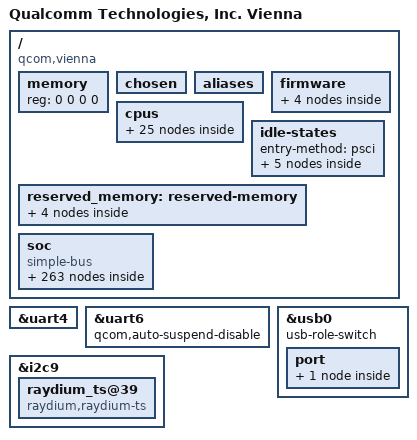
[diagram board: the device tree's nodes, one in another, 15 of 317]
// SPDX-License-Identifier: BSD-3-Clause
/*
 * Copyright (c) Qualcomm Technologies, Inc. and/or its subsidiaries.
 */

#include <dt-bindings/clock/qcom,gcc-vienna.h>
#include <dt-bindings/clock/qcom,gpucc-vienna.h>
#include <dt-bindings/clock/qcom,rpmh.h>
#include <dt-bindings/dma/qcom-gpi.h>
#include <dt-bindings/interrupt-controller/arm-gic.h>
#include <dt-bindings/interconnect/qcom,icc.h>
#include <dt-bindings/interconnect/qcom,vienna.h>
#include <dt-bindings/soc/qcom,rpmh-rsc.h>
#include <dt-bindings/soc/qcom,ipcc.h>
#include <dt-bindings/mailbox/qcom-ipcc-vienna.h>
#include <dt-bindings/regulator/qcom,rpmh-regulator-levels.h>
#include <dt-bindings/spmi/spmi.h>

/ {
	model = "Qualcomm Technologies, Inc. Vienna";
	compatible = "qcom,vienna";
	qcom,msm-id = <669 0x10000 >;
	interrupt-parent = <&intc>;
	#address-cells = <2>;
	#size-cells = <2>;
	memory { device_type = "memory"; reg = <0 0 0 0>; };

	chosen: chosen {
		bootargs = "android_arch_task_struct_size=512 kasan=off kpti=0 log_buf_len=256K swiotlb=0 loop.max_part=7 irqaffinity=0-1 cpufreq.default_governor=performance printk.console_no_auto_verbose=1 rcupdate.rcu_expedited=1 rcu_nocbs=0-4 kernel.panic_on_rcu_stall=1 androidboot.usbcontroller=a600000.dwc3";
	};

	aliases {
		serial0 = &uart4;
		hsuart1 = &uart6;
		i2c0 = &i2c0;
		i2c1 = &i2c1;
		i2c2 = &i2c2_a;
		i2c3 = &i2c3_a;
		i2c4 = &i2c4;
		i2c5 = &i2c5_a;
		i2c6 = &i2c6;
		i2c7 = &i2c7_a;
		i2c8 = &i2c8;
		i2c9 = &i2c9;
		i2c10 = &i2c10;
		i2c11 = &i2c2_b;
		i2c12 = &i2c3_b;
		i2c13 = &i2c5_b;
		i2c14 = &i2c7_b;
		spi0 = &spi0;
		spi1 = &spi1;
		spi2 = &spi2_a;
		spi3 = &spi3_a;
		spi4 = &spi4;
		spi5 = &spi5_a;
		spi6 = &spi6;
		spi7 = &spi7_a;
		spi8 = &spi8;
		spi9 = &spi9;
		spi10 = &spi10;
		spi11 = &spi2_b;
		spi12 = &spi3_b;
		spi13 = &spi5_b;
		spi14 = &spi7_b;
		mmc0 = &sdhc_1;
		mmc1 = &sdhc_3; /*SDC3 SDIO slot*/
	};

	firmware: firmware {

		qcom_scm: qcom_scm {
			compatible = "qcom,scm";
			qcom,dload-mode = <&tcsr 0x19000>;
		};

		qtee_shmbridge {
			compatible = "qcom,tee-shared-memory-bridge";
		};

		qcom_smcinvoke {
			compatible = "qcom,smcinvoke";
		};

		qcom_mem_object {
			compatible = "qcom,mem-object";
		};
	};

	cpus {
		#address-cells = <2>;
		#size-cells = <0>;
		CPU0: cpu@0 {
			device_type = "cpu";
			compatible = "qcom,kryo";
			reg = <0x0 0x0>;
			enable-method = "psci";
			d-cache-size = <0x8000>;
			i-cache-size = <0x8000>;
			cpu-idle-states = <&SILVER_RAIL_OFF>;
			power-domains = <&CPU_PD0>;
			power-domain-names = "psci";
			next-level-cache = <&L2_0>;
			qcom,freq-domain = <&cpufreq_hw 0>;
			capacity-dmips-mhz = <1024>;
			dynamic-power-coefficient = <100>;
			#cooling-cells = <2>;
			L2_0: l2-cache {
			      cache-level = <2>;
			      compatible = "cache";
			      cache-size = <0x10000>;
			};

			L1_I_0: l1-icache {
			      compatible = "cache";
			};

			L1_D_0: l1-dcache {
			      compatible = "cache";
			};
		};

		CPU1: cpu@100 {
			device_type = "cpu";
			compatible = "qcom,kryo";
			reg = <0x0 0x100>;
			enable-method = "psci";
			d-cache-size = <0x8000>;
			i-cache-size = <0x8000>;
			cpu-idle-states = <&SILVER_RAIL_OFF>;
			power-domains = <&CPU_PD1>;
			power-domain-names = "psci";
			next-level-cache = <&L2_0>;
			qcom,freq-domain = <&cpufreq_hw 0>;
			capacity-dmips-mhz = <1024>;
			dynamic-power-coefficient = <100>;
			#cooling-cells = <2>;

			L1_I_1: l1-icache {
			      compatible = "cache";
			};

			L1_D_1: l1-dcache {
			      compatible = "cache";
			};
		};

		CPU2: cpu@200 {
			device_type = "cpu";
			compatible = "qcom,kryo";
			reg = <0x0 0x200>;
			enable-method = "psci";
			d-cache-size = <0x8000>;
			i-cache-size = <0x8000>;
			cpu-idle-states = <&SILVER_RAIL_OFF>;
			power-domains = <&CPU_PD2>;
			power-domain-names = "psci";
			next-level-cache = <&L2_0>;
			qcom,freq-domain = <&cpufreq_hw 0>;
			capacity-dmips-mhz = <1024>;
			dynamic-power-coefficient = <100>;
			#cooling-cells = <2>;

			L1_I_2: l1-icache {
			      compatible = "cache";
			};

			L1_D_2: l1-dcache {
			      compatible = "cache";
			};
		};

		CPU3: cpu@300 {
			device_type = "cpu";
			compatible = "qcom,kryo";
			reg = <0x0 0x300>;
			enable-method = "psci";
			d-cache-size = <0x8000>;
			i-cache-size = <0x8000>;
			cpu-idle-states = <&SILVER_RAIL_OFF>;
			power-domains = <&CPU_PD3>;
			power-domain-names = "psci";
			next-level-cache = <&L2_0>;
			qcom,freq-domain = <&cpufreq_hw 0>;
			capacity-dmips-mhz = <1024>;
			dynamic-power-coefficient = <100>;
			#cooling-cells = <2>;

			L1_I_3: l1-icache {
			      compatible = "cache";
			};

			L1_D_3: l1-dcache {
			      compatible = "cache";
			};
		};

		CPU4: cpu@400 {
			device_type = "cpu";
			compatible = "qcom,kryo";
			reg = <0x0 0x400>;
			enable-method = "psci";
			d-cache-size = <0x8000>;
			i-cache-size = <0x8000>;
			cpu-idle-states = <&GOLD_OFF &GOLD_RAIL_OFF>;
			power-domains = <&CPU_PD4>;
			power-domain-names = "psci";
			next-level-cache = <&L2_1>;
			qcom,freq-domain = <&cpufreq_hw 1>;
			capacity-dmips-mhz = <1946>;
			dynamic-power-coefficient = <472>;
			#cooling-cells = <2>;
			L2_1: l2-cache {
			      cache-level = <2>;
			      compatible = "cache";
			      cache-size = <0x40000>;
			};

			L1_I_4: l1-icache {
			      compatible = "cache";
			};

			L1_D_4: l1-dcache {
			      compatible = "cache";
			};
		};

		cpu-map {
			cluster0 {
				core0 {
					cpu = <&CPU0>;
				};

				core1 {
					cpu = <&CPU1>;
				};

				core2 {
					cpu = <&CPU2>;
				};

				core3 {
					cpu = <&CPU3>;
				};
			};

			cluster1 {
				core0 {
					cpu = <&CPU4>;
				};
			};
		};
	};

	idle-states {
		entry-method = "psci";

		GOLD_OFF: gold-c3 {  /* C3 */
			compatible = "arm,idle-state";
			idle-state-name = "pc";
			entry-latency-us = <400>;
			exit-latency-us = <1050>;
			min-residency-us = <5773>;
			arm,psci-suspend-param = <0x40000003>;
			local-timer-stop;
		};

		GOLD_RAIL_OFF: gold-cluster0-c4 { /* C4 */
			compatible = "arm,idle-state";
			idle-state-name = "rail-pc";
			entry-latency-us = <550>;
			exit-latency-us = <1100>;
			min-residency-us = <9016>;
			arm,psci-suspend-param = <0x40000004>;
			local-timer-stop;
		};

		SILVER_RAIL_OFF: silver-cluster1-c4 { /* C4 */
			compatible = "arm,idle-state";
			idle-state-name = "rail-pc";
			entry-latency-us = <550>;
			exit-latency-us = <900>;
			min-residency-us = <6700>;
			arm,psci-suspend-param = <0x40000004>;
			local-timer-stop;
		};

		CLUSTER_PWR_DN: cluster-d4 { /* D4 */
			compatible = "domain-idle-state";
			idle-state-name = "l3-off";
			entry-latency-us = <750>;
			exit-latency-us = <2350>;
			min-residency-us = <9144>;
			arm,psci-suspend-param = <0x41000044>;
		};

		CX_RET: cx-ret { /* Cx Ret */
			compatible = "domain-idle-state";
			idle-state-name = "cx-ret";
			entry-latency-us = <2800>;
			exit-latency-us = <4400>;
			min-residency-us = <10901>;
			arm,psci-suspend-param = <0x41003344>;
		};
	};

	reserved_memory: reserved-memory { };

	soc: soc { };
};

&qcom_scm {
	compatible = "qcom,scm";
};

&soc {
	#address-cells = <1>;
	#size-cells = <1>;
	ranges = <0 0 0 0xffffffff>;
	compatible = "simple-bus";

	psci {
		compatible = "arm,psci-1.0";
		method = "smc";

		CPU_PD0: cpu-pd0 {
			#power-domain-cells = <0>;
			power-domains = <&CLUSTER_PD>;
		};

		CPU_PD1: cpu-pd1 {
			#power-domain-cells = <0>;
			power-domains = <&CLUSTER_PD>;
		};

		CPU_PD2: cpu-pd2 {
			#power-domain-cells = <0>;
			power-domains = <&CLUSTER_PD>;
		};

		CPU_PD3: cpu-pd3 {
			#power-domain-cells = <0>;
			power-domains = <&CLUSTER_PD>;
		};

		CPU_PD4: cpu-pd4 {
			#power-domain-cells = <0>;
			power-domains = <&CLUSTER_PD>;
		};

		CLUSTER_PD: cluster-pd {
			#power-domain-cells = <0>;
			domain-idle-states = <&CLUSTER_PWR_DN &CX_RET>;
		};
	};

	msm_gpu: qcom,kgsl-3d0@3d00000 { };

	intc: interrupt-controller@17200000 {
		compatible = "arm,gic-v3";
		#interrupt-cells = <3>;
		interrupt-controller;
		#redistributor-regions = <1>;
		redistributor-stride = <0x0 0x20000>;
		reg = <0x17200000 0x10000>,	// GICD
		      <0x17260000 0xA0000>;	// GICR * 5
		interrupts = <GIC_PPI 9 IRQ_TYPE_LEVEL_HIGH>;
	};

	qcom_tzlog: tz-log@14680720 {
		compatible = "qcom,tz-log";
		reg = <0x14680720 0x3000>;
		qcom,hyplog-enabled;
		hyplog-address-offset = <0x410>;
		hyplog-size-offset = <0x414>;
		tmecrashdump-address-offset = <0x81CA0000>;
	};

	memtimer: timer@17420000 {
		#address-cells = <1>;
		#size-cells = <1>;
		ranges;
		compatible = "arm,armv7-timer-mem";
		reg = <0x17420000 0x1000>;
		clock-frequency = <19200000>;
		frame@17421000 {
			frame-number = <0>;
			interrupts = <GIC_SPI 8 IRQ_TYPE_LEVEL_HIGH>,
				     <GIC_SPI 6 IRQ_TYPE_LEVEL_HIGH>;
			reg = <0x17421000 0x1000>,
			      <0x17422000 0x1000>;
		};

		frame@17423000 {
			frame-number = <1>;
			interrupts = <GIC_SPI 9 IRQ_TYPE_LEVEL_HIGH>;
			reg = <0x17423000 0x1000>;
			status = "disabled";
		};

		frame@17425000 {
			frame-number = <2>;
			interrupts = <GIC_SPI 10 IRQ_TYPE_LEVEL_HIGH>;
			reg = <0x17425000 0x1000>;
			status = "disabled";
		};

		frame@17427000 {
			frame-number = <3>;
			interrupts = <GIC_SPI 11 IRQ_TYPE_LEVEL_HIGH>;
			reg = <0x17427000 0x1000>;
			status = "disabled";
		};

		frame@17429000 {
			frame-number = <4>;
			interrupts = <GIC_SPI 12 IRQ_TYPE_LEVEL_HIGH>;
			reg = <0x17429000 0x1000>;
			status = "disabled";
		};

		frame@1742b000 {
			frame-number = <5>;
			interrupts = <GIC_SPI 13 IRQ_TYPE_LEVEL_HIGH>;
			reg = <0x1742b000 0x1000>;
			status = "disabled";
		};

		frame@1742d000 {
			frame-number = <6>;
			interrupts = <GIC_SPI 14 IRQ_TYPE_LEVEL_HIGH>;
			reg = <0x1742d000 0x1000>;
			status = "disabled";
		};
	};

	wdog: qcom,wdt@17410000 {
		compatible = "qcom,msm-watchdog";
		reg = <0x17410000 0x1000>;
		reg-names = "wdt-base";
		interrupts = <GIC_SPI 0 IRQ_TYPE_LEVEL_HIGH>,
			     <GIC_SPI 1 IRQ_TYPE_LEVEL_HIGH>;
		qcom,bark-time = <11000>;
		qcom,pet-time = <9360>;
		qcom,ipi-ping;
		qcom,wakeup-enable;
		status = "ok";
	};

	google,debug-kinfo {
		compatible = "google,debug-kinfo";
		memory-region = <&kinfo_mem>;
	};

	mini_dump_mode {
		compatible = "qcom,minidump";
		status = "ok";
	};

	apps_rsc: rsc@17a00000 {
		label = "apps_rsc";
		compatible = "qcom,rpmh-rsc";
		reg = <0x17a00000 0x10000>,
		      <0x17a10000 0x10000>,
		      <0x17a20000 0x10000>;
		reg-names = "drv-0", "drv-1", "drv-2";
		qcom,drv-count = <3>;
		interrupts = <GIC_SPI 3 IRQ_TYPE_LEVEL_HIGH>,
			     <GIC_SPI 4 IRQ_TYPE_LEVEL_HIGH>,
			     <GIC_SPI 5 IRQ_TYPE_LEVEL_HIGH>;
		power-domains = <&CLUSTER_PD>;

		apps_rsc_drv2: drv@2 {
			qcom,drv-id = <2>;
			qcom,tcs-offset = <0xd00>;
			qcom,tcs-distance = <0x2a0>;
			channel@0 {
				qcom,tcs-config = <ACTIVE_TCS    3>,
						  <SLEEP_TCS     2>,
						  <WAKE_TCS      2>,
						  <CONTROL_TCS   0>,
						  <FAST_PATH_TCS 1>;
			};

			apps_bcm_voter: bcm_voter {
				compatible = "qcom,bcm-voter";
			};

			rpmhcc: clock-controller {
				compatible = "qcom,vienna-rpmh-clk";
				#clock-cells = <1>;
			};
		};
	};

	cluster-device {
		compatible = "qcom,lpm-cluster-dev";
		power-domains = <&CLUSTER_PD>;
	};

	qcom,secure-buffer {
		compatible = "qcom,secure-buffer";
		qcom,vmid-cp-camera-preview-ro;
	};

	pdc: interrupt-controller@b220000 {
		compatible = "qcom,vienna-pdc", "qcom,pdc";
		reg = <0xb220000 0x10000>, <0x174000f0 0x64>;
		qcom,pdc-ranges = <0 456 30>, <38 663 9>, <51 527 47>,
				  <98 608 32>, <130 716 12>, <142 251 5>,
				  <147 584 16>;
		#interrupt-cells = <2>;
		interrupt-parent = <&intc>;
		interrupt-controller;
	};

	show_resume_irqs@17200000 {
		compatible = "qcom,show-resume-irqs";
		reg = <0x17200000 0x130000>;	/* GICD */
	};

	arch_timer: timer {
		compatible = "arm,armv8-timer";
		interrupts = <GIC_PPI 13 (GIC_CPU_MASK_SIMPLE(8) | IRQ_TYPE_LEVEL_LOW)>,
			     <GIC_PPI 14 (GIC_CPU_MASK_SIMPLE(8) | IRQ_TYPE_LEVEL_LOW)>,
			     <GIC_PPI 11 (GIC_CPU_MASK_SIMPLE(8) | IRQ_TYPE_LEVEL_LOW)>,
			     <GIC_PPI 12 (GIC_CPU_MASK_SIMPLE(8) | IRQ_TYPE_LEVEL_LOW)>;
		clock-frequency = <19200000>;
	};

	sdhc1_opp_table: sdhc1-opp-table {
		compatible = "operating-points-v2";

		opp-100000000 {
			opp-hz = /bits/ 64 <100000000>;
			opp-peak-kBps = <250000 133320>;
			opp-avg-kBps = <104000 0>;
		};

		opp-384000000 {
			opp-hz = /bits/ 64 <384000000>;
			opp-peak-kBps = <800000 300000>;
			opp-avg-kBps = <400000 0>;
		};
	};

	sdhc3_opp_table: sdhc3-opp-table {
		compatible = "operating-points-v2";

		opp-100000000 {
			opp-hz = /bits/ 64 <100000000>;
			opp-peak-kBps = <160000 100000>;
			opp-avg-kBps = <50000 0>;
		};

		opp-202000000 {
			opp-hz = /bits/ 64 <202000000>;
			opp-peak-kBps = <200000 120000>;
			opp-avg-kBps = <104000 0>;
		};
	};

	sdhc_1: sdhci@8804000 {
		compatible = "qcom,sdhci-msm-v5";
		status = "disabled";

		reg = <0x08804000 0x1000>,<0x08805000 0x1000>,<0x08808000 0x18000>;
		reg-names = "hc", "cqhci", "ice";

		iommus = <&apps_smmu 0x0120 0x0>;
		qcom,iommu-dma = "fastmap";

		/*
		 * iommu-addresses - Indicate the range of data addresses which will be
		 * used in dma allocation.
		 *
		 * iommu-geometry -  This is specific for fastmap which Allow clients
		 * to save SMMU page table memory.
		 *
		 * The 2nd parameter indicates size of the smmu page table memory.
		 * If its exceeds beyond this size, last unused entry from page table
		 * memory will be invalidated.
		 *
		 * It's better to provide range of dma address, hence provide
		 * iommu-dma-addr-pool property along with iommu-geometry property.
		 */

		qcom,iommu-addresses = <0x40000000 0x10000000>;
		qcom,iommu-geometry = <0x40000000 0x10000000>;

		interrupts = <GIC_SPI 207 IRQ_TYPE_LEVEL_HIGH>,
			<GIC_SPI 223 IRQ_TYPE_LEVEL_HIGH>;
		interrupt-names = "hc_irq", "pwr_irq";

		clocks = <&gcc GCC_SDCC1_APPS_CLK>,
			<&gcc GCC_SDCC1_AHB_CLK>,
			<&gcc GCC_SDCC1_ICE_CORE_CLK>;
		clock-names = "core", "iface", "ice_core";

		qcom,ice-clk-rates = <300000000 100000000>;

		interconnects = <&aggre_noc MASTER_SDCC_1 &mc_virt SLAVE_EBI1>,
				<&gem_noc MASTER_APPSS_PROC &config_noc SLAVE_SDCC_1>;
		interconnect-names = "sdhc-ddr","cpu-sdhc";
		operating-points-v2 = <&sdhc1_opp_table>;

		/* DLL HSR settings. Refer go/hsr - <Target> DLL settings */
		qcom,dll-hsr-list = <0x000F44EC 0x0 0x01 0x290106C0 0x80040868>;

		qcom,ice-use-hwkm;
		bus-width = <8>;

		supports-cqe;
		dma-coherent;

		cap-mmc-hw-reset;

		qcom,restore-after-cx-collapse;

		no-sd;
		no-sdio;

		non-removable;

		resets = <&gcc GCC_SDCC1_BCR>;
		reset-names = "core_reset";

		qos0 {
			mask = <0x10>;
			vote = <44>;
		};

		qos1 {
			mask = <0x0f>;
			vote = <44>;
		};
	};

	qcom,msm-imem@14680000 {
		compatible = "qcom,msm-imem";
		reg = <0x14680000 0x1000>;
		ranges = <0x0 0x14680000 0x1000>;
		#address-cells = <1>;
		#size-cells = <1>;

		mem_dump_table@10 {
			compatible = "qcom,msm-imem-mem_dump_table";
			reg = <0x10 0x8>;
		};

		restart_reason@65c {
			compatible = "qcom,msm-imem-restart_reason";
			reg = <0x65c 0x4>;
		};

		dload_type@1c {
			compatible = "qcom,msm-imem-dload-type";
			reg = <0x1c 0x4>;
		};

		boot_stats@6b0 {
			compatible = "qcom,msm-imem-boot_stats";
			reg = <0x6b0 0x20>;
		};

		kaslr_offset@6d0 {
			compatible = "qcom,msm-imem-kaslr_offset";
			reg = <0x6d0 0xc>;
		};

		pil@94c {
			compatible = "qcom,pil-reloc-info";
			reg = <0x94c 0xc8>;
		};

		pil@6dc {
			compatible = "qcom,msm-imem-pil-disable-timeout";
			reg = <0x6dc 0x4>;
		};

		diag_dload@c8 {
			compatible = "qcom,msm-imem-diag-dload";
			reg = <0xc8 0xc8>;
		};

		modem_dsm@c98 {
			compatible = "qcom,msm-imem-mss-dsm";
			reg = <0xc98 0x10>;
		};
	};

	ipcc_mproc: qcom,ipcc@1105000 {
		compatible = "qcom,ipcc";
		reg = <0x01105000 0x1000>;
		interrupts = <GIC_SPI 366 IRQ_TYPE_LEVEL_HIGH>;
		interrupt-controller;
		#interrupt-cells = <3>;
		#mbox-cells = <2>;
	};

	sys-pm-vx@c320000 {
		compatible = "qcom,sys-pm-violators", "qcom,sys-pm-vienna";
		qcom,qmp = <&aoss_qmp>;
		reg = <0xc320000 0x400>;
	};

	tcsr_mutex_block: syscon@1f40000 {
		compatible = "syscon";
		reg = <0x1f40000 0x20000>;
	};

	tcsr: syscon@1fc0000 {
		compatible = "syscon";
		reg = <0x1fc0000 0x30000>;
	};

	tcsr_mutex: hwlock {
		compatible = "qcom,tcsr-mutex";
		syscon = <&tcsr_mutex_block 0 0x1000>;
		#hwlock-cells = <1>;
	};

	eud: qcom,msm-eud@88e0000 {
		compatible = "qcom,msm-eud";
		interrupt-names = "eud_irq";
		interrupt-parent = <&pdc>;
		interrupts = <17 IRQ_TYPE_LEVEL_HIGH>;
		reg = <0x88e0000 0x2000>,
			<0x88e2000 0x1000>;
		reg-names = "eud_base", "eud_mode_mgr2";
		qcom,secure-eud-en;
		status = "ok";
	};

	va_mini_dump {
		compatible = "qcom,va-minidump";
		memory-region = <&va_md_mem>;
	};

	cache-controller@24800000 {
		compatible = "qcom,vienna-llcc";
		reg = <0x24800000 0x200000>;
		reg-names = "llcc0_base";
		interrupts = <GIC_SPI 266 IRQ_TYPE_LEVEL_HIGH>;
		cap-based-alloc-and-pwr-collapse;
	};

	gic-interrupt-router {
		compatible = "qcom,gic-intr-routing";
		/* keep a few m cores in class0 only to avoid wakeup of l cores */
		qcom,gic-class0-cpus = <&CPU0 &CPU1 &CPU2 &CPU3>;
		/* keep other cores in class1 */
		qcom,gic-class1-cpus = <&CPU4>;
	};

	kryo-erp {
		compatible = "arm,arm64-kryo-cpu-erp";
		interrupts = <GIC_PPI 0 IRQ_TYPE_LEVEL_HIGH>,
			<GIC_SPI 35 IRQ_TYPE_LEVEL_HIGH>;
		interrupt-names = "l1-l2-faultirq","l3-scu-faultirq";
	};

	qcom,rmtfs_sharedmem@0 {
		compatible = "qcom,sharedmem-uio";
		reg = <0x0 0x400000>;
		reg-names = "rmtfs";
		qcom,client-id = <0x00000001>;
	};

	qcom,mem-buf {
		compatible = "qcom,mem-buf";
		qcom,mem-buf-capabilities = "supplier";
		qcom,vmid = <3>;
	};

	qcom,mem-buf-msgq {
		compatible = "qcom,mem-buf-msgq";
	};

	cpu_pmu: cpu-pmu {
		compatible = "arm,armv8-pmuv3";
		interrupts = <GIC_PPI 7 IRQ_TYPE_LEVEL_HIGH>;
	};

	llcc_pmu: llcc-pmu@24095000 {
		compatible = "qcom,llcc-pmu-ver2";
		reg = <0x24095000 0x300>;
		reg-names = "lagg-base";
	};

	qcom_pmu: qcom,pmu {
		compatible = "qcom,pmu";
		qcom,pmu-events-tbl =
			< 0x0008 0x3F 0xFF 0xFF >,
			< 0x0011 0x3F 0xFF 0xFF >,
			< 0x0017 0x3F 0xFF 0xFF >,
			< 0x002A 0x3F 0xFF 0xFF >,
			< 0x1000 0x3F 0xFF 0xFF >;
	};

	qfprom: qfprom@351c8000 {
		compatible = "qcom,vienna-qfprom", "qcom,qfprom";
		reg = <0x351c8000 0x1000>;
		#address-cells = <1>;
		#size-cells = <1>;
		read-only;
		ranges;

		gpu_speed_bin: gpu_speed_bin@138 {
			reg = <0x138 0x1>;
			bits = <0 8>;
		};
	};

	sdhc_3: sdhci@8844000 {
		compatible = "qcom,sdhci-msm-v5";
		status = "disabled";
		reg = <0x08844000 0x1000>;
		reg-names = "hc";

		interrupts = <GIC_SPI 261 IRQ_TYPE_LEVEL_HIGH>,
			<GIC_SPI 227 IRQ_TYPE_LEVEL_HIGH>;
		interrupt-names = "hc_irq", "pwr_irq";

		clocks = <&gcc GCC_SDCC2_APPS_CLK>, <&gcc GCC_SDCC2_AHB_CLK>;
		clock-names = "core", "iface";

		interconnects = <&aggre_noc MASTER_SDCC_2 &mc_virt SLAVE_EBI1>,
			<&gem_noc MASTER_APPSS_PROC &config_noc SLAVE_SDCC_2>;
		interconnect-names = "sdhc-ddr","cpu-sdhc";
		operating-points-v2 = <&sdhc3_opp_table>;

		/* DLL HSR settings. Refer go/hsr - <Target> DLL settings */
		qcom,dll-hsr-list = <0x0007442C 0x0 0x10 0x290106C0 0x80040868>;

		bus-width = <4>;
		cap-sd-highspeed;
		sd-uhs-sdr12;
		sd-uhs-sdr25;
		sd-uhs-sdr50;
		sd-uhs-ddr50;
		max-frequency = <86000000>;

		iommus = <&apps_smmu 0x140 0x0>;
		qcom,iommu-dma = "bypass";

		qos0 {
			mask = <0x10>;
			vote = <44>;
		};

		qos1 {
			mask = <0x0f>;
			vote = <44>;
		};
	};

	cpucp: qcom,cpucp@17400000 {
		#address-cells = <2>;
		#size-cells = <2>;
		compatible = "qcom,cpucp";
		reg = <0x17400000 0x10>,
			<0x17d90000 0x2000>;
		reg-names = "tx", "rx";
		#mbox-cells = <1>;
		interrupts = <GIC_SPI 62 IRQ_TYPE_LEVEL_HIGH>;
	};

	aoss_qmp: power-controller@c300000 {
		compatible = "qcom,aoss-qmp";
		reg = <0xc300000 0x400>;
		interrupt-parent = <&ipcc_mproc>;
		interrupts = <IPCC_MPROC_AOP
			      IPCC_MPROC_SIGNAL_GLINK_QMP
			      IRQ_TYPE_EDGE_RISING>;
		mboxes = <&ipcc_mproc IPCC_MPROC_AOP
			  IPCC_MPROC_SIGNAL_GLINK_QMP>;

		#power-domain-cells = <1>;
		#clock-cells = <0>;
	};

	qmp_tme: qcom,qmp-tme {
		compatible = "qcom,qmp-mbox";
		qcom,remote-pid = <14>;
		mboxes = <&ipcc_mproc IPCC_MPROC_TMESS
			  IPCC_MPROC_SIGNAL_GLINK_QMP>;
		mbox-names = "tme_qmp";
		interrupt-parent = <&ipcc_mproc>;
		interrupts = <IPCC_MPROC_TMESS
			      IPCC_MPROC_SIGNAL_GLINK_QMP
			      IRQ_TYPE_EDGE_RISING>;

		label = "tme";
		qcom,early-boot;
		priority = <0>;
		mbox-desc-offset = <0x0>;
		#mbox-cells = <1>;
	};

	qcom,tmecom-qmp-client {
		compatible = "qcom,tmecom-qmp-client";
		mboxes = <&qmp_tme 0>;
		mbox-names = "tmecom";
		label = "tmecom";
		depends-on-supply = <&qmp_tme>;
	};

	qcom,sps {
		compatible = "qcom,msm-sps-4k";
		qcom,pipe-attr-ee;
	};

	qcom_cedev: qcedev@1de0000 {
		compatible = "qcom,qcedev";
		reg = <0x1de0000 0x20000>,
		<0x1dc4000 0x28000>;
		reg-names = "crypto-base","crypto-bam-base";
		interrupts = <GIC_SPI 272 IRQ_TYPE_LEVEL_HIGH>;
		qcom,bam-pipe-pair = <2>;
		qcom,offload-ops-support;
		qcom,use-key-index;
		qcom,bam-pipe-offload-cpb-hlos = <1>;
		qcom,bam-pipe-offload-hlos-cpb = <3>;
		qcom,bam-pipe-offload-hlos-cpb-1 = <8>;
		qcom,bam-pipe-offload-hlos-hlos = <4>;
		qcom,bam-pipe-offload-hlos-hlos-1 = <9>;
		qcom,ce-hw-instance = <0>;
		qcom,ce-device = <0>;
		qcom,ce-hw-shared;
		qcom,bam-ee = <0>;
		qcom,smmu-s1-enable;
		qcom,no-clock-support;
		qcom,no-clk-gating;
		interconnect-names = "data_path";
		interconnects = <&aggre_noc MASTER_CRYPTO &mc_virt SLAVE_EBI1>;
		iommus = <&apps_smmu 0x0080 0x0>,
		<&apps_smmu 0x0081 0x0>;
		qcom,iommu-dma = "atomic";
		dma-coherent;

		qcom_cedev_ns_cb {
			compatible = "qcom,qcedev,context-bank";
			label = "ns_context";
			iommus = <&apps_smmu 0x0081 0x0>;
			dma-coherent;
		};

		qcom_cedev_s_cb {
			compatible = "qcom,qcedev,context-bank";
			label = "secure_context";
			iommus = <&apps_smmu 0x0083 0x0>;
			qcom,iommu-vmid = <0x9>;
			qcom,secure-context-bank;
			dma-noncoherent;
		};
	};

	qcom_rng: qrng@10c3000 {
		compatible = "qcom,msm-rng";
		reg = <0x10c3000 0x1000>;
		qcom,no-qrng-config;
		qcom,no-clock-support;
	};

	qcom,mem-buf {
		compatible = "qcom,mem-buf";
		qcom,mem-buf-capabilities = "supplier";
		qcom,vmid = <3>;
	};

	qcom,mem-buf-msgq {
		compatible = "qcom,mem-buf-msgq";
	};

	qcom,smp2p-adsp {
		compatible = "qcom,smp2p";
		qcom,smem = <443>, <429>;
		interrupt-parent = <&ipcc_mproc>;
		interrupts = <IPCC_MPROC_LPASS IPCC_MPROC_SIGNAL_SMP2P
			      IRQ_TYPE_EDGE_RISING>;
		mboxes = <&ipcc_mproc IPCC_MPROC_LPASS
			  IPCC_MPROC_SIGNAL_SMP2P>;
		qcom,local-pid = <0>;
		qcom,remote-pid = <2>;

		adsp_smp2p_out: master-kernel {
			qcom,entry-name = "master-kernel";
			#qcom,smem-state-cells = <1>;
		};

		adsp_smp2p_in: slave-kernel {
			qcom,entry-name = "slave-kernel";
			interrupt-controller;
			#interrupt-cells = <2>;
		};

		sleepstate_smp2p_out: sleepstate-out {
			qcom,entry-name = "sleepstate";
			#qcom,smem-state-cells = <1>;
		};

		sleepstate_smp2p_in: qcom,sleepstate-in {
			qcom,entry-name = "sleepstate_see";
			interrupt-controller;
			#interrupt-cells = <2>;
		};

		smp2p_rdbg2_out: qcom,smp2p-rdbg2-out {
			qcom,entry-name = "rdbg";
			#qcom,smem-state-cells = <1>;
		};

		smp2p_rdbg2_in: qcom,smp2p-rdbg2-in {
			qcom,entry-name = "rdbg";
			interrupt-controller;
			#interrupt-cells = <2>;
		};
	};

	qcom,smp2p-cdsp {
		compatible = "qcom,smp2p";
		qcom,smem = <94>, <432>;
		interrupt-parent = <&ipcc_mproc>;
		interrupts = <IPCC_MPROC_CDSP IPCC_MPROC_SIGNAL_SMP2P
			      IRQ_TYPE_EDGE_RISING>;
		mboxes = <&ipcc_mproc IPCC_MPROC_CDSP IPCC_MPROC_SIGNAL_SMP2P>;
		qcom,local-pid = <0>;
		qcom,remote-pid = <5>;

		cdsp_smp2p_out: master-kernel {
			qcom,entry-name = "master-kernel";
			#qcom,smem-state-cells = <1>;
		};

		cdsp_smp2p_in: slave-kernel {
			qcom,entry-name = "slave-kernel";
			interrupt-controller;
			#interrupt-cells = <2>;
		};

		smp2p_rdbg5_out: qcom,smp2p-rdbg5-out {
			qcom,entry-name = "rdbg";
			#qcom,smem-state-cells = <1>;
		};

		smp2p_rdbg5_in: qcom,smp2p-rdbg5-in {
			qcom,entry-name = "rdbg";
			interrupt-controller;
			#interrupt-cells = <2>;
		};
	};

	qcom,smp2p-modem {
		compatible = "qcom,smp2p";
		qcom,smem = <435>, <428>;
		interrupt-parent = <&ipcc_mproc>;
		interrupts = <IPCC_MPROC_MPSS IPCC_MPROC_SIGNAL_SMP2P
			      IRQ_TYPE_EDGE_RISING>;
		mboxes = <&ipcc_mproc IPCC_MPROC_MPSS IPCC_MPROC_SIGNAL_SMP2P>;
		qcom,local-pid = <0>;
		qcom,remote-pid = <1>;

		modem_smp2p_out: master-kernel {
			qcom,entry-name = "master-kernel";
			#qcom,smem-state-cells = <1>;
		};

		modem_smp2p_in: slave-kernel {
			qcom,entry-name = "slave-kernel";
			interrupt-controller;
			#interrupt-cells = <2>;
		};

		smp2p_ipa_1_out: qcom,smp2p-ipa-1-out {
			qcom,entry-name = "ipa";
			#qcom,smem-state-cells = <1>;
		};

		/* ipa - inbound entry from mss */
		smp2p_ipa_1_in: qcom,smp2p-ipa-1-in {
			qcom,entry-name = "ipa";
			interrupt-controller;
			#interrupt-cells = <2>;
		};

		smp2p_smem_mailbox_1_out: qcom,smp2p-smem-mailbox-1-out {
			qcom,entry-name = "smem-mailbox";
			#qcom,smem-state-cells = <1>;
		};

		smp2p_smem_mailbox_1_in: qcom,smp2p-smem-mailbox-1-in {
			qcom,entry-name = "smem-mailbox";
			interrupt-controller;
			#interrupt-cells = <2>;
		};
	};

	qcom,smp2p-dcp {
		compatible = "qcom,smp2p";
		qcom,smem = <617>, <616>;
		interrupt-parent = <&ipcc_mproc>;
		interrupts = <IPCC_MPROC_DCP IPCC_MPROC_SIGNAL_SMP2P
			      IRQ_TYPE_EDGE_RISING>;
		mboxes = <&ipcc_mproc IPCC_MPROC_DCP IPCC_MPROC_SIGNAL_SMP2P>;
		qcom,local-pid = <0>;
		qcom,remote-pid = <22>;

		dcp_smp2p_out: master-kernel {
			qcom,entry-name = "master-kernel";
			#qcom,smem-state-cells = <1>;
		};

		dcp_smp2p_in: slave-kernel {
			qcom,entry-name = "slave-kernel";
			interrupt-controller;
			#interrupt-cells = <2>;
		};
	};

	qcom,smp2p-wm {
		compatible = "qcom,smp2p";
		qcom,smem = <617>, <616>;
		interrupt-parent = <&ipcc_mproc>;
		interrupts = <IPCC_MPROC_M55_WM IPCC_MPROC_SIGNAL_SMP2P
				  IRQ_TYPE_EDGE_RISING>;
		mboxes = <&ipcc_mproc IPCC_MPROC_M55_WM IPCC_MPROC_SIGNAL_SMP2P>;
		qcom,local-pid = <0>;
		qcom,remote-pid = <23>;

		wm_smp2p_out: master-kernel {
			qcom,entry-name = "master-kernel";
			#qcom,smem-state-cells = <1>;
		};

		wm_smp2p_in: slave-kernel {
			qcom,entry-name = "slave-kernel";
			interrupt-controller;
			#interrupt-cells = <2>;
		};
	};

	qcom,smp2p-am {
		compatible = "qcom,smp2p";
		qcom,smem = <617>, <616>;
		interrupt-parent = <&ipcc_mproc>;
		interrupts = <IPCC_MPROC_M55_AM IPCC_MPROC_SIGNAL_SMP2P
				  IRQ_TYPE_EDGE_RISING>;
		mboxes = <&ipcc_mproc IPCC_MPROC_M55_AM IPCC_MPROC_SIGNAL_SMP2P>;
		qcom,local-pid = <0>;
		qcom,remote-pid = <24>;

		am_smp2p_out: master-kernel {
			qcom,entry-name = "master-kernel";
			#qcom,smem-state-cells = <1>;
		};

		am_smp2p_in: slave-kernel {
			qcom,entry-name = "slave-kernel";
			interrupt-controller;
			#interrupt-cells = <2>;
		};
	};

	qcom,smp2p_sleepstate {
		compatible = "qcom,smp2p-sleepstate";
		qcom,smem-states = <&sleepstate_smp2p_out 0>;
		interrupt-parent = <&sleepstate_smp2p_in>;
		interrupts = <0 0>;
		interrupt-names = "smp2p-sleepstate-in";
	};

	clocks {
		xo_board: xo_board {
			compatible = "fixed-clock";
			clock-frequency = <38400000>;
			clock-output-names = "xo_board";
			#clock-cells = <0>;
		};

		sleep_clk: sleep_clk {
			compatible = "fixed-clock";
			clock-frequency = <32000>;
			clock-output-names = "sleep_clk";
			#clock-cells = <0>;
		};

		pcie_0_pipe_clk: pcie_0_pipe_clk {
			compatible = "fixed-clock";
			clock-frequency = <1000>;
			clock-output-names = "pcie_0_pipe_clk";
			#clock-cells = <0>;
		};

		usb3_phy_wrapper_gcc_usb30_pipe_clk: usb3_phy_wrapper_gcc_usb30_pipe_clk {
			compatible = "fixed-clock";
			clock-frequency = <1000>;
			clock-output-names = "usb3_phy_wrapper_gcc_usb30_pipe_clk";
			#clock-cells = <0>;
		};
	};

	cpuss-sleep-stats@17800054 {
		compatible = "qcom,cpuss-sleep-stats-v5";
		reg = <0x17800054 0x4>, <0x17810054 0x4>, <0x17820054 0x4>,
		      <0x17830054 0x4>, <0x17840054 0x4>, <0x17880098 0x4>,
		      <0x178c0000 0x10000>;
		reg-names = "seq_lpm_cntr_cfg_cpu0", "seq_lpm_cntr_cfg_cpu1",
			    "seq_lpm_cntr_cfg_cpu2", "seq_lpm_cntr_cfg_cpu3",
			    "seq_lpm_cntr_cfg_cpu4", "l3_seq_lpm_cntr_cfg",
			    "apss_seq_mem_base";
		num-cpus = <5>;
	};

	sram@c3f0000 {
		compatible = "qcom,rpmh-stats-v4";
		reg = <0x0c3f0000 0x400>;
		qcom,qmp = <&aoss_qmp>;
		ss-name = "modem", "adsp", "adsp_island",
			  "cdsp", "apss", "soccp", "dcp";
	};

	gcc: clock-controller@100000 {
		compatible = "qcom,vienna-gcc", "syscon";
		reg = <0x100000 0x1f4200>;
		reg-name = "cc_base";
		vdd_cx-supply = <&VDD_CX_LEVEL>;
		vdd_mx-supply = <&VDD_MXA_LEVEL>;
		vdd_mxc-supply = <&VDD_MXC_LEVEL>;
		clocks = <&rpmhcc RPMH_CXO_CLK>,
			 <&pcie_0_pipe_clk>,
			 <&sleep_clk>,
			 <&usb3_phy_wrapper_gcc_usb30_pipe_clk>;
		clock-names = "bi_tcxo",
			      "pcie_0_pipe_clk",
			      "sleep_clk",
			      "usb3_phy_wrapper_gcc_usb30_pipe_clk";
		#clock-cells = <1>;
		#reset-cells = <1>;
	};

	gpucc: clock-controller@3d90000 {
		compatible = "qcom,vienna-gpucc", "syscon";
		reg = <0x3d90000 0xa000>;
		reg-name = "cc_base";
		vdd_cx-supply = <&VDD_CX_LEVEL>;
		vdd_mx-supply = <&VDD_MXA_LEVEL>;
		vdd_mxc-supply = <&VDD_MXC_LEVEL>;
		clocks = <&rpmhcc RPMH_CXO_CLK>,
			 <&gcc GCC_GPU_GPLL0_CLK_SRC>,
			 <&gcc GCC_GPU_GPLL0_DIV_CLK_SRC>;
		clock-names = "bi_tcxo",
			      "gpll0_out_main",
			      "gpll0_out_main_div";
		#clock-cells = <1>;
		#reset-cells = <1>;
	};

	apsscc: syscon@17aa0000 {
		compatible = "syscon";
		reg = <0x17aa0000 0x1c>;
	};

	mccc: syscon@240ba000 {
		compatible = "syscon";
		reg = <0x240ba000 0x54>;
	};

	debugcc: clock-controller@0 {
		compatible = "qcom,vienna-debugcc";
		qcom,apsscc = <&apsscc>;
		qcom,gcc = <&gcc>;
		qcom,gpucc = <&gpucc>;
		qcom,mccc = <&mccc>;
		clocks = <&rpmhcc RPMH_CXO_CLK>,
			 <&gcc 0>,
			 <&gpucc 0>;
		clock-names = "xo_clk_src",
			      "gcc",
			      "gpucc";
		#clock-cells = <1>;
	};

	gcc_apcs_gdsc_vote_ctrl: syscon@152184 {
		compatible = "syscon";
		reg = <0x152184 0x4>;
	};

	/* GCC GDSCs */
	gcc_camss_top_gdsc: qcom,gdsc@12a004 {
		compatible = "qcom,gdsc";
		reg = <0x12a004 0x4>;
		regulator-name = "gcc_camss_top_gdsc";
		parent-supply = <&VDD_MXC_LEVEL>;
		qcom,retain-regs;
		qcom,support-cfg-gdscr;
	};

	gcc_pcie_0_gdsc: qcom,gdsc@16b004 {
		compatible = "qcom,gdsc";
		reg = <0x16b004 0x4>;
		regulator-name = "gcc_pcie_0_gdsc";
		parent-supply = <&VDD_CX_LEVEL>;
		qcom,retain-regs;
		qcom,no-status-check-on-disable;
		qcom,collapse-vote = <&gcc_apcs_gdsc_vote_ctrl 0>;
		qcom,support-cfg-gdscr;
	};

	gcc_pcie_0_phy_gdsc: qcom,gdsc@16c000 {
		compatible = "qcom,gdsc";
		reg = <0x16c000 0x4>;
		regulator-name = "gcc_pcie_0_phy_gdsc";
		parent-supply = <&VDD_MXA_LEVEL>;
		qcom,retain-regs;
		qcom,no-status-check-on-disable;
		qcom,collapse-vote = <&gcc_apcs_gdsc_vote_ctrl 2>;
		qcom,support-cfg-gdscr;
	};

	gcc_usb30_prim_gdsc: qcom,gdsc@159004 {
		compatible = "qcom,gdsc";
		reg = <0x159004 0x4>;
		regulator-name = "gcc_usb30_prim_gdsc";
		parent-supply = <&VDD_CX_LEVEL>;
		qcom,retain-regs;
		qcom,support-cfg-gdscr;
	};

	gcc_vcodec0_gdsc: qcom,gdsc@12c004 {
		compatible = "qcom,gdsc";
		reg = <0x12c004 0x4>;
		regulator-name = "gcc_vcodec0_gdsc";
		parent-supply = <&VDD_MXC_LEVEL>;
		qcom,retain-regs;
		qcom,support-hw-trigger;
		qcom,support-cfg-gdscr;
	};

	gcc_venus_gdsc: qcom,gdsc@12b01c {
		compatible = "qcom,gdsc";
		reg = <0x12b01c 0x4>;
		regulator-name = "gcc_venus_gdsc";
		parent-supply = <&VDD_MXC_LEVEL>;
		qcom,retain-regs;
		qcom,support-cfg-gdscr;
	};

	/* GPU_CC GDSCs */
	gpu_cc_cx_gdsc_hw_ctrl: syscon@3d99484 {
		compatible = "syscon";
		reg = <0x3d99484 0x4>;
	};

	gpu_cc_cx_gdsc: qcom,gdsc@3d99110 {
		compatible = "qcom,gdsc";
		reg = <0x3d99110 0x4>;
		regulator-name = "gpu_cc_cx_gdsc";
		parent-supply = <&VDD_CX_LEVEL>;
		hw-ctrl-addr = <&gpu_cc_cx_gdsc_hw_ctrl>;
		qcom,no-status-check-on-disable;
		qcom,clk-dis-wait-val = <8>;
		qcom,retain-regs;
	};

	gpu_cc_gx_gdsc: qcom,gdsc@3d9905c {
		compatible = "qcom,gdsc";
		reg = <0x3d9905c 0x4>;
		regulator-name = "gpu_cc_gx_gdsc";
		parent-supply = <&VDD_GFX_LEVEL>;
		qcom,retain-regs;
		qcom,support-cfg-gdscr;
	};

	cpufreq_hw: qcom,cpufreq-hw {
		compatible = "qcom,cpufreq-epss";
		reg = <0x17D91000 0x1000>,
		      <0x17D92000 0x1000>;
		reg-names = "freq-domain0",
			    "freq-domain1";
		clocks = <&rpmhcc RPMH_CXO_CLK>, <&gcc GCC_GPLL0>;
		clock-names = "xo", "alternate";
		interrupts = <GIC_SPI 30 IRQ_TYPE_LEVEL_HIGH>,
			     <GIC_SPI 31 IRQ_TYPE_LEVEL_HIGH>;
		interrupt-names = "dcvsh0_int",
				  "dcvsh1_int";
		#freq-domain-cells = <1>;
	};

	qcom,cpufreq-hw-debug {
		compatible = "qcom,cpufreq-hw-epss-debug";
		qcom,freq-hw-domain = <&cpufreq_hw 0>,
				      <&cpufreq_hw 1>;
	};

	qcom,mpm2-sleep-counter@c221000 {
		compatible = "qcom,mpm2-sleep-counter";
		reg = <0xc221000 0x1000>;
		clock-frequency = <32768>;
	};

	clk_virt: interconnect@0 {
		compatible = "qcom,vienna-clk_virt";
		#interconnect-cells = <1>;
		qcom,bcm-voter-names = "hlos";
		qcom,bcm-voters = <&apps_bcm_voter>;
	};

	mc_virt: interconnect@1 {
		compatible = "qcom,vienna-mc_virt";
		#interconnect-cells = <1>;
		qcom,bcm-voter-names = "hlos";
		qcom,bcm-voters = <&apps_bcm_voter>;
	};

	aggre_noc: interconnect@16E0000 {
		compatible = "qcom,vienna-aggre_noc";
		reg = <0x016E0000 0x1F400>;
		#interconnect-cells = <1>;
		qcom,bcm-voter-names = "hlos";
		qcom,bcm-voters = <&apps_bcm_voter>;
		clocks = <&gcc GCC_AGGRE_USB3_PRIM_AXI_CLK>,
			 <&gcc GCC_SDCC1_AHB_CLK>,
			 <&gcc GCC_SDCC2_AHB_CLK>,
			 <&rpmhcc RPMH_IPA_CLK>;
	};

	gem_noc: interconnect@24100000 {
		compatible = "qcom,vienna-gem_noc";
		reg = <0x24100000 0x17F080>;
		#interconnect-cells = <1>;
		qcom,bcm-voter-names = "hlos";
		qcom,bcm-voters = <&apps_bcm_voter>;
	};

	mmss_noc: interconnect@1780000 {
		compatible = "qcom,vienna-mmss_noc";
		reg = <0x01780000 0x5B400>;
		#interconnect-cells = <1>;
		qcom,bcm-voter-names = "hlos";
		qcom,bcm-voters = <&apps_bcm_voter>;
	};

	nsp_noc: interconnect@320C0000 {
		compatible = "qcom,vienna-nsp_noc";
		reg = <0x320C0000 0x1F400>;
		#interconnect-cells = <1>;
		qcom,bcm-voter-names = "hlos";
		qcom,bcm-voters = <&apps_bcm_voter>;
	};

	system_noc: interconnect@1680000 {
		compatible = "qcom,vienna-system_noc";
		reg = <0x01680000 0x40000>;
		#interconnect-cells = <1>;
		qcom,bcm-voter-names = "hlos";
		qcom,bcm-voters = <&apps_bcm_voter>;
	};

	lpass_lpiaon_noc: interconnect@22000000 {
		compatible = "qcom,vienna-lpass_lpiaon_noc";
		reg = <0x22000000 0x19080>;
		#interconnect-cells = <1>;
		qcom,bcm-voter-names = "hlos";
		qcom,bcm-voters = <&apps_bcm_voter>;
	};

	lpass_lpicx_noc: interconnect@22020000 {
		compatible = "qcom,vienna-lpass_lpicx_noc";
		reg = <0x22020000 0x5F400>;
		#interconnect-cells = <1>;
		qcom,bcm-voter-names = "hlos";
		qcom,bcm-voters = <&apps_bcm_voter>;
	};

	lpass_ag_noc: interconnect@23E40000 {
		compatible = "qcom,vienna-lpass_ag_noc";
		reg = <0x23E40000 0xE080>;
		#interconnect-cells = <1>;
		qcom,bcm-voter-names = "hlos";
		qcom,bcm-voters = <&apps_bcm_voter>;
	};

	config_noc: interconnect@1600000 {
		compatible = "qcom,vienna-cnoc_cfg";
		reg = <0x1600000 0x7400>;
		#interconnect-cells = <1>;
		qcom,bcm-voter-names = "hlos";
		qcom,bcm-voters = <&apps_bcm_voter>;
	};

	cnoc_main: interconnect@1500000 {
		compatible = "qcom,vienna-cnoc_main";
		reg = <0x01500000 0x16400>;
		#interconnect-cells = <1>;
		qcom,bcm-voter-names = "hlos";
		qcom,bcm-voters = <&apps_bcm_voter>;
	};

	pcie_noc: interconnect@16C0000 {
		compatible = "qcom,vienna-pcie_anoc";
		reg = <0x016C0000 0x11400>;
		#interconnect-cells = <1>;
		qcom,bcm-voter-names = "hlos";
		qcom,bcm-voters = <&apps_bcm_voter>;
		clocks = <&gcc GCC_AGGRE_NOC_PCIE_AXI_CLK>,
			 <&gcc GCC_CFG_NOC_PCIE_ANOC_AHB_CLK>;
	};

	qcom,msm-adsprpc-mem {
		compatible = "qcom,msm-adsprpc-mem-region";
		memory-region = <&adsp_mem_heap>;
		restrict-access;
	};

	adsp_pas: remoteproc-adsp@03000000 {
		compatible = "qcom,vienna-adsp-pas";
		reg = <0x03000000 0x10000>;
		status = "ok";

		cx-supply = <&VDD_LPI_CX_LEVEL>;
		cx-uV-uA = <RPMH_REGULATOR_LEVEL_TURBO 0>;
		mx-supply = <&VDD_LPI_MX_LEVEL>;
		mx-uV-uA = <RPMH_REGULATOR_LEVEL_TURBO 0>;
		reg-names = "cx", "mx";

		clocks = <&rpmhcc RPMH_CXO_CLK>;
		clock-names = "xo";

		qcom,qmp = <&aoss_qmp>;

		interconnects = <&lpass_lpicx_noc MASTER_LPASS_PROC &mc_virt SLAVE_EBI1>,
				<&aggre_noc MASTER_CRYPTO &mc_virt SLAVE_EBI1>;

		interconnect-names = "rproc_ddr", "crypto_ddr";

		firmware-name = "adsp.mdt", "adsp_dtb.mdt";

		memory-region = <&adspslpi_mem &q6_adsp_dtb_mem>;
		subdev-memory-region = <&wear_microcontroller_m55_mem &ambient_microcontroller_m55_mem>;

		/* Inputs from ssc */
		interrupts-extended = <&pdc 6 IRQ_TYPE_EDGE_RISING>,
					<&adsp_smp2p_in 0 0>,
					<&adsp_smp2p_in 2 0>,
					<&adsp_smp2p_in 1 0>,
					<&adsp_smp2p_in 3 0>,
					<&adsp_smp2p_in 7 0>;

		interrupt-names = "wdog",
				"fatal",
				"handover",
				"ready",
				"stop-ack",
				"shutdown-ack";

		/* Outputs to turing */
		qcom,smem-states = <&adsp_smp2p_out 0>;
		qcom,smem-state-names = "stop";

		remoteproc_adsp_glink: glink-edge {
			qcom,remote-pid = <2>;
			transport = "smem";
			mboxes = <&ipcc_mproc IPCC_MPROC_LPASS
				  IPCC_MPROC_SIGNAL_GLINK_QMP>;
			mbox-names = "adsp_smem";
			interrupt-parent = <&ipcc_mproc>;
			interrupts = <IPCC_MPROC_LPASS
				      IPCC_MPROC_SIGNAL_GLINK_QMP
				      IRQ_TYPE_EDGE_RISING>;

			label = "adsp";
			qcom,glink-label = "lpass";

			qcom,adsp_qrtr {
				qcom,glink-channels = "IPCRTR";
				qcom,net-id = <2>;
				qcom,intents = <0x800  5
						0x2000 3
						0x4400 2>;

				qcom,no-wake-svc = <0x190>;
			};
		};
	};

	modem_pas: remoteproc-mss@04080000 {
		compatible = "qcom,vienna-modem-pas";
		reg = <0x04080000 0x10000>;
		status = "ok";

		cx-supply = <&VDD_CX_LEVEL>;
		cx-uV-uA = <RPMH_REGULATOR_LEVEL_TURBO 100000>;
		mx-supply = <&VDD_MXC_LEVEL>;
		mx-uV-uA = <RPMH_REGULATOR_LEVEL_TURBO 100000>;
		reg-names = "cx", "mx";

		clocks = <&rpmhcc RPMH_CXO_CLK>;
		clock-names = "xo";

		qcom,qmp = <&aoss_qmp>;

		interconnects = <&mc_virt MASTER_LLCC &mc_virt SLAVE_EBI1>,
				<&aggre_noc MASTER_CRYPTO &mc_virt SLAVE_EBI1>;

		interconnect-names = "rproc_ddr", "crypto_ddr";

		firmware-name = "modem.mdt", "modem_dtb.mdt";

		memory-region = <&mpss_mem &q6_mpss_dtb_mem>;

		/* Inputs from mss */
		interrupts-extended = <&intc GIC_SPI 264 IRQ_TYPE_EDGE_RISING>,
					<&modem_smp2p_in 0 0>,
					<&modem_smp2p_in 2 0>,
					<&modem_smp2p_in 1 0>,
					<&modem_smp2p_in 3 0>,
					<&modem_smp2p_in 7 0>;

		interrupt-names = "wdog",
				"fatal",
				"handover",
				"ready",
				"stop-ack",
				"shutdown-ack";

		/* Outputs to mss */
		qcom,smem-states = <&modem_smp2p_out 0>;
		qcom,smem-state-names = "stop";

		glink-edge {
			qcom,remote-pid = <1>;
			transport = "smem";
			mboxes = <&ipcc_mproc IPCC_MPROC_MPSS
				  IPCC_MPROC_SIGNAL_GLINK_QMP>;
			mbox-names = "mpss_smem";
			interrupt-parent = <&ipcc_mproc>;
			interrupts = <IPCC_MPROC_MPSS
				      IPCC_MPROC_SIGNAL_GLINK_QMP
				      IRQ_TYPE_EDGE_RISING>;

			label = "modem";
			qcom,glink-label = "mpss";

			qcom,modem_qrtr {
				qcom,glink-channels = "IPCRTR";
				qcom,low-latency;
				qcom,intents = <0x800  5
						0x2000 3
						0x4400 2>;
			};

			qcom,modem_ds {
				qcom,glink-channels = "DS";
				qcom,intents = <0x4000 0x2>;
			};
		};
	};

	cdsp_pas: remoteproc-cdsp@32300000 {
		compatible = "qcom,vienna-cdsp-pas";
		reg = <0x32300000 0x10000>;
		status = "ok";

		cx-supply = <&VDD_CX_LEVEL>;
		cx-uV-uA = <RPMH_REGULATOR_LEVEL_TURBO 100000>;
		mx-supply = <&VDD_MXC_LEVEL>;
		mx-uV-uA = <RPMH_REGULATOR_LEVEL_TURBO 100000>;
		nsp-supply = <&VDD_NSP_LEVEL>;
		nsp-uV-uA = <RPMH_REGULATOR_LEVEL_TURBO 100000>;
		reg-names = "cx","mx","nsp";

		clocks = <&rpmhcc RPMH_CXO_CLK>;
		clock-names = "xo";

		qcom,qmp = <&aoss_qmp>;
		interconnects = <&nsp_noc MASTER_CDSP_PROC &mc_virt SLAVE_EBI1>,
				<&aggre_noc MASTER_CRYPTO &mc_virt SLAVE_EBI1>;

		interconnect-names = "rproc_ddr", "crypto_ddr";

		firmware-name = "cdsp.mdt", "cdsp_dtb.mdt";
		memory-region = <&cdsp_mem &q6_cdsp_dtb_mem>;

		/* Inputs from turing */
		interrupts-extended = <&intc GIC_SPI 578 IRQ_TYPE_EDGE_RISING>,
					<&cdsp_smp2p_in 0 0>,
					<&cdsp_smp2p_in 2 0>,
					<&cdsp_smp2p_in 1 0>,
					<&cdsp_smp2p_in 3 0>,
					<&cdsp_smp2p_in 7 0>;

		interrupt-names = "wdog",
				"fatal",
				"handover",
				"ready",
				"stop-ack",
				"shutdown-ack";

		/* Outputs to turing */
		qcom,smem-states = <&cdsp_smp2p_out 0>;
		qcom,smem-state-names = "stop";

		remoteproc_cdsp_glink: glink-edge {
			qcom,remote-pid = <5>;
			transport = "smem";
			mboxes = <&ipcc_mproc IPCC_MPROC_CDSP
				  IPCC_MPROC_SIGNAL_GLINK_QMP>;
			mbox-names = "cdsp_smem";
			interrupt-parent = <&ipcc_mproc>;
			interrupts = <IPCC_MPROC_CDSP
				      IPCC_MPROC_SIGNAL_GLINK_QMP
				      IRQ_TYPE_EDGE_RISING>;

			label = "cdsp";
			qcom,glink-label = "cdsp";

			qcom,cdsp_qrtr {
				qcom,glink-channels = "IPCRTR";
				qcom,intents = <0x800  5
						0x2000 3
						0x4400 2>;
			};
		};
	};

	vendor_hooks: qcom,cpu-vendor-hooks {
		compatible = "qcom,cpu-vendor-hooks";
	};

	qcom,glink {
		compatible = "qcom,glink";
		#address-cells = <1>;
		#size-cells = <1>;
		ranges;

		glink_wm: wm {
			qcom,remote-pid = <23>;
			transport = "smem";
			mboxes = <&ipcc_mproc IPCC_MPROC_M55_WM
				  IPCC_MPROC_SIGNAL_GLINK_QMP>;
			mbox-names = "wm_smem";
			interrupt-parent = <&ipcc_mproc>;
			interrupts = <IPCC_MPROC_M55_WM
				      IPCC_MPROC_SIGNAL_GLINK_QMP
				      IRQ_TYPE_EDGE_RISING>;

			label = "wm";
			qcom,ssr-label = "lpass";

			qcom,glinkpkt-wm-qsh-0 {
				qcom,glink-channels = "qsh_2_0";
				qcom,intents = <0x1000 3
						0x3E8  7>;
			};

			qcom,glinkpkt-wm-qsh-1 {
				qcom,glink-channels = "qsh_2_1";
				qcom,intents = <0x1000 3
						0x3E8  7>;
			};

			qcom,glinkpkt-wm-qsh-2 {
				qcom,glink-channels = "qsh_2_2";
				qcom,intents = <0x1000 3
						0x3E8  7>;
			};

			qcom,glinkpkt-wm-qsh-3 {
				qcom,glink-channels = "qsh_2_3";
				qcom,intents = <0x1000 3
						0x3E8  7>;
			};

			qcom,glinkpkt-wm-qsh-4 {
				qcom,glink-channels = "qsh_2_4";
				qcom,intents = <0x1000 3
						0x3E8  7>;
			};

			qcom,glinkpkt-wm-qsh-5 {
				qcom,glink-channels = "qsh_2_5";
				qcom,intents = <0x1000 3
						0x3E8  7>;
			};

			qcom,glinkpkt-wm-qsh-6 {
				qcom,glink-channels = "qsh_2_6";
				qcom,intents = <0x1000 3
						0x3E8  7>;
			};

			qcom,glinkpkt-wm-qsh-7 {
				qcom,glink-channels = "qsh_2_7";
				qcom,intents = <0x1000 3
						0x3E8  7>;
			};

			qcom,glinkpkt-wm-qsh-8 {
				qcom,glink-channels = "qsh_2_8";
				qcom,intents = <0x1000 3
						0x3E8  7>;
			};
		};

		glink_am: am {
			qcom,remote-pid = <24>;
			transport = "smem";
			mboxes = <&ipcc_mproc IPCC_MPROC_M55_AM
				  IPCC_MPROC_SIGNAL_GLINK_QMP>;
			mbox-names = "am_smem";
			interrupt-parent = <&ipcc_mproc>;
			interrupts = <IPCC_MPROC_M55_AM
				      IPCC_MPROC_SIGNAL_GLINK_QMP
				      IRQ_TYPE_EDGE_RISING>;

			label = "am";
			qcom,ssr-label = "lpass";

			qcom,glinkpkt-am-touch {
			qcom,glink-channels = "touch-ctrl";
			qcom,intents = <0x200 1>;
			};
		};
	};

	qcom_glinkpkt: qcom,glinkpkt {
		compatible = "qcom,glinkpkt";

		qcom,glinkpkt-ctrl-cdsp {
				qcom,glinkpkt-edge = "cdsp";
				qcom,glinkpkt-ch-name = "LOOPBACK_CTL_CDSP";
				qcom,glinkpkt-dev-name = "glink_pkt_ctrl_cdsp";
		};

		qcom,glinkpkt-data-cdsp {
				qcom,glinkpkt-edge = "cdsp";
				qcom,glinkpkt-ch-name = "LOOPBACK_DATA_CDSP";
				qcom,glinkpkt-dev-name = "glink_pkt_data_cdsp";
		};

		qcom,glinkpkt-ctrl-lpass {
				qcom,glinkpkt-edge = "lpass";
				qcom,glinkpkt-ch-name = "LOOPBACK_CTL_LPASS";
				qcom,glinkpkt-dev-name = "glink_pkt_ctrl_lpass";
		};

		qcom,glinkpkt-data-lpass {
				qcom,glinkpkt-edge = "lpass";
				qcom,glinkpkt-ch-name = "LOOPBACK_DATA_LPASS";
				qcom,glinkpkt-dev-name = "glink_pkt_data_lpass";
		};

		qcom,glinkpkt-ctrl-mpss {
				qcom,glinkpkt-edge = "mpss";
				qcom,glinkpkt-ch-name = "LOOPBACK_CTL_MPSS";
				qcom,glinkpkt-dev-name = "glink_pkt_ctrl_mpss";
		};

		qcom,glinkpkt-data-mpss {
				qcom,glinkpkt-edge = "mpss";
				qcom,glinkpkt-ch-name = "LOOPBACK_DATA_MPSS";
				qcom,glinkpkt-dev-name = "glink_pkt_data_mpss";
		};

		qcom,glinkpkt-ctrl-am {
				qcom,glinkpkt-edge = "am";
				qcom,glinkpkt-ch-name = "LOOPBACK_CTL_AM";
				qcom,glinkpkt-dev-name = "glink_pkt_ctrl_am";
		};

		qcom,glinkpkt-disp-ctrl-am {
				qcom,glinkpkt-edge = "am";
				qcom,glinkpkt-ch-name = "disp-ctrl";
				qcom,glinkpkt-dev-name = "glink_pkt_am_display_ctrl";
		};

		qcom,glinkpkt-data-am {
				qcom,glinkpkt-edge = "am";
				qcom,glinkpkt-ch-name = "LOOPBACK_DATA_AM";
				qcom,glinkpkt-dev-name = "glink_pkt_data_am";
		};

		qcom,glinkpkt-ctrl-wm {
				qcom,glinkpkt-edge = "wm";
				qcom,glinkpkt-ch-name = "LOOPBACK_CTL_WM";
				qcom,glinkpkt-dev-name = "glink_pkt_ctrl_wm";
		};

		qcom,glinkpkt-data-wm {
				qcom,glinkpkt-edge = "wm";
				qcom,glinkpkt-ch-name = "LOOPBACK_DATA_WM";
				qcom,glinkpkt-dev-name = "glink_pkt_data_wm";
		};

		qcom,glinkpkt-am-diag-cntl {
			qcom,glinkpkt-edge = "am";
			qcom,glinkpkt-ch-name = "DIAG_AM_CNTL";
			qcom,glinkpkt-dev-name = "diag_am_cntl";
		};

		qcom,glinkpkt-am-diag-cmd {
			qcom,glinkpkt-edge = "am";
			qcom,glinkpkt-ch-name = "DIAG_AM_CMD";
			qcom,glinkpkt-dev-name = "diag_am_cmd";
		};

		qcom,glinkpkt-am-diag-data {
			qcom,glinkpkt-edge = "am";
			qcom,glinkpkt-ch-name = "DIAG_AM_DATA";
			qcom,glinkpkt-dev-name = "diag_am_data";
		};

		qcom,glinkpkt-wm-diag-cntl {
			qcom,glinkpkt-edge = "wm";
			qcom,glinkpkt-ch-name = "DIAG_WM_CNTL";
			qcom,glinkpkt-dev-name = "diag_wm_cntl";
		};

		qcom,glinkpkt-wm-diag-cmd {
			qcom,glinkpkt-edge = "wm";
			qcom,glinkpkt-ch-name = "DIAG_WM_CMD";
			qcom,glinkpkt-dev-name = "diag_wm_cmd";
		};

		qcom,glinkpkt-wm-diag-data {
			qcom,glinkpkt-edge = "wm";
			qcom,glinkpkt-ch-name = "DIAG_WM_DATA";
			qcom,glinkpkt-dev-name = "diag_wm_data";
		};

		qcom,glinkpkt-at-mdm0 {
			qcom,glinkpkt-edge = "mpss";
			qcom,glinkpkt-ch-name = "DS";
			qcom,glinkpkt-dev-name = "at_mdm0";
		};

		qcom,glinkpkt-apr-apps2 {
			qcom,glinkpkt-edge = "adsp";
			qcom,glinkpkt-ch-name = "apr_apps2";
			qcom,glinkpkt-dev-name = "apr_apps2";
		};

		qcom,glinkpkt-data40-cntl {
			qcom,glinkpkt-edge = "mpss";
			qcom,glinkpkt-ch-name = "DATA40_CNTL";
			qcom,glinkpkt-dev-name = "smdcntl8";
		};

		qcom,glinkpkt-data1 {
			qcom,glinkpkt-edge = "mpss";
			qcom,glinkpkt-ch-name = "DATA1";
			qcom,glinkpkt-dev-name = "smd7";
		};

		qcom,glinkpkt-data4 {
			qcom,glinkpkt-edge = "mpss";
			qcom,glinkpkt-ch-name = "DATA4";
			qcom,glinkpkt-dev-name = "smd8";
		};

		qcom,glinkpkt-data11 {
			qcom,glinkpkt-edge = "mpss";
			qcom,glinkpkt-ch-name = "DATA11";
			qcom,glinkpkt-dev-name = "smd11";
		};

		qcom,glinkpkt-qmc-dma {
			qcom,glinkpkt-edge = "mpss";
			qcom,glinkpkt-ch-name = "QMC_DMA_LINE";
			qcom,glinkpkt-dev-name = "qmc_dma";
			qcom,glinkpkt-enable-ch-close;
		};

		qcom,glinkpkt-qmc-cma {
			qcom,glinkpkt-edge = "mpss";
			qcom,glinkpkt-ch-name = "QMC_CMA_LINE";
			qcom,glinkpkt-dev-name = "qmc_cma";
			qcom,glinkpkt-enable-ch-close;
		};

		qcom,glinkpkt-xpan_control {
			qcom,glinkpkt-edge = "adsp";
			qcom,glinkpkt-ch-name = "bt_cp_ctrl";
			qcom,glinkpkt-dev-name = "bt_cp_ctrl";
		};

		qcom,glinkpkt-hci-aribter {
			qcom,glinkpkt-edge = "lpass";
			qcom,glinkpkt-ch-name = "hci_arbiter_chnl";
			qcom,glinkpkt-dev-name = "glink_pkt_hci_arbiter_chnl";
			qcom,intents = <0x1000 10>;
			qcom,glinkpkt-enable-ch-close;
		};

		qcom,glinkpkt-socket-offload {
			qcom,glinkpkt-edge = "lpass";
			qcom,glinkpkt-ch-name = "bt_socket_hal_chnl";
			qcom,glinkpkt-dev-name = "glink_pkt_bt_socket_hal_chnl";
			qcom,intents = <0x1000 10>;
			qcom,glinkpkt-enable-ch-close;
		};

		qcom,glinkpkt-gatt-offload {
			qcom,glinkpkt-edge = "lpass";
			qcom,glinkpkt-ch-name = "gatt_offload_chnl";
			qcom,glinkpkt-dev-name = "glink_pkt_bt_gatt_offload_chnl";
			qcom,intents = <0x1000 10>;
			qcom,glinkpkt-enable-ch-close;
		 };

		qcom,glinkpkt-wm-qsh-0 {
			qcom,glinkpkt-edge = "wm";
			qcom,glinkpkt-ch-name = "qsh_2_0";
			qcom,glinkpkt-dev-name = "glinkpkt_wm_qsh_2_0";
			qcom,glinkpkt-enable-ch-close;
		};

		qcom,glinkpkt-wm-qsh-1 {
			qcom,glinkpkt-edge = "wm";
			qcom,glinkpkt-ch-name = "qsh_2_1";
			qcom,glinkpkt-dev-name = "glinkpkt_wm_qsh_2_1";
			qcom,glinkpkt-enable-ch-close;
		};

		qcom,glinkpkt-wm-qsh-2 {
			qcom,glinkpkt-edge = "wm";
			qcom,glinkpkt-ch-name = "qsh_2_2";
			qcom,glinkpkt-dev-name = "glinkpkt_wm_qsh_2_2";
			qcom,glinkpkt-enable-ch-close;
		};

		qcom,glinkpkt-wm-qsh-3 {
			qcom,glinkpkt-edge = "wm";
			qcom,glinkpkt-ch-name = "qsh_2_3";
			qcom,glinkpkt-dev-name = "glinkpkt_wm_qsh_2_3";
			qcom,glinkpkt-enable-ch-close;
		};

		qcom,glinkpkt-wm-qsh-4 {
			qcom,glinkpkt-edge = "wm";
			qcom,glinkpkt-ch-name = "qsh_2_4";
			qcom,glinkpkt-dev-name = "glinkpkt_wm_qsh_2_4";
			qcom,glinkpkt-enable-ch-close;
		};

		qcom,glinkpkt-wm-qsh-5 {
			qcom,glinkpkt-edge = "wm";
			qcom,glinkpkt-ch-name = "qsh_2_5";
			qcom,glinkpkt-dev-name = "glinkpkt_wm_qsh_2_5";
			qcom,glinkpkt-enable-ch-close;
		};

		qcom,glinkpkt-wm-qsh-6 {
			qcom,glinkpkt-edge = "wm";
			qcom,glinkpkt-ch-name = "qsh_2_6";
			qcom,glinkpkt-dev-name = "glinkpkt_wm_qsh_2_6";
			qcom,glinkpkt-enable-ch-close;
		};

		qcom,glinkpkt-wm-qsh-7 {
			qcom,glinkpkt-edge = "wm";
			qcom,glinkpkt-ch-name = "qsh_2_7";
			qcom,glinkpkt-dev-name = "glinkpkt_wm_qsh_2_7";
			qcom,glinkpkt-enable-ch-close;
		};

		qcom,glinkpkt-wm-qsh-8 {
			qcom,glinkpkt-edge = "wm";
			qcom,glinkpkt-ch-name = "qsh_2_8";
			qcom,glinkpkt-dev-name = "glinkpkt_wm_qsh_2_8";
			qcom,glinkpkt-enable-ch-close;
		};

		qcom,glinkpkt-contexthub-hal-app-mgr-chnl {
			qcom,glinkpkt-edge = "am";
			qcom,glinkpkt-ch-name = "contexthub_hal_app_mgr_chnl";
			qcom,glinkpkt-dev-name = "glink_pkt_contexthub_hal_app_mgr_chnl";
			qcom,intents = <0x1000 10>;
			qcom,glinkpkt-enable-ch-close;
		};

		qcom,glinkpkt-contexthub-hal-offload-mgr-chnl {
			qcom,glinkpkt-edge = "lpass";
			qcom,glinkpkt-ch-name = "contexthub_hal_offload_mgr_chnl";
			qcom,glinkpkt-dev-name = "glink_pkt_contexthub_hal_offload_mgr_chnl";
			qcom,intents = <0x1000 10>;
			qcom,glinkpkt-enable-ch-close;
		};
	};

	thermal_zones: thermal-zones {};

	spmi_bus: spmi0_bus: qcom,spmi@c42d000 {
		compatible = "qcom,spmi-pmic-arb";
		reg = <0xc42d000 0x4000>,
		      <0xc400000 0x3000>,
		      <0xc500000 0x400000>,
		      <0xc440000 0x80000>,
		      <0xc4c0000 0x10000>;
		reg-names = "cnfg", "core", "chnls", "obsrvr", "intr";
		interrupts-extended = <&pdc 1 IRQ_TYPE_LEVEL_HIGH>;
		interrupt-names = "periph_irq";
		interrupt-controller;
		#interrupt-cells = <4>;
		#address-cells = <2>;
		#size-cells = <0>;
		cell-index = <0>;
		qcom,channel = <0>;
		qcom,ee = <0>;
		qcom,bus-id = <0>;
	};

	spmi0_debug_bus: qcom,spmi-debug@11314000 {
		compatible = "qcom,spmi-pmic-arb-debug";
		reg = <0x11314000 0x60>, <0x351c8780 0x4>;
		reg-names = "core", "fuse";
		clocks = <&aoss_qmp>;
		clock-names = "core_clk";
		qcom,fuse-enable-bit = <14>;
		#address-cells = <2>;
		#size-cells = <0>;
		depends-on-supply = <&spmi_bus>;

		pmw6100@0 {
			compatible = "qcom,spmi-pmic";
			reg = <0 SPMI_USID>;
			#address-cells = <2>;
			#size-cells = <0>;
			qcom,can-sleep;
		};

		pm8010@c {
			compatible = "qcom,spmi-pmic";
			reg = <12 SPMI_USID>;
			#address-cells = <2>;
			#size-cells = <0>;
			qcom,can-sleep;
			status = "disabled";
		};
	};

	qcom,pmic_glink {
		compatible = "qcom,qti-pmic-glink";
		qcom,pmic-glink-channel = "PMIC_RTR_ADSP_APPS";
		qcom,subsys-name = "lpass";
		qcom,protection-domain = "tms/servreg", "msm/adsp/charger_pd";
		depends-on-supply = <&ipcc_mproc>;

		battery_charger: qcom,battery_charger {
			compatible = "qcom,battery-charger";
		};

		ucsi: qcom,ucsi {
			compatible = "qcom,ucsi-glink";
		};

		altmode: qcom,altmode {
			compatible = "qcom,altmode-glink";
			#altmode-cells = <1>;
		};
	};

	qcom,pmic_glink_log {
		compatible = "qcom,qti-pmic-glink";
		qcom,pmic-glink-channel = "PMIC_LOGS_ADSP_APPS";

		qcom,battery_debug {
			compatible = "qcom,battery-debug";
		};

		qcom,charger_ulog_glink {
			compatible = "qcom,charger-ulog-glink";
		};

		pmic_glink_debug: qcom,pmic_glink_debug {
			compatible = "qcom,pmic-glink-debug";
			#address-cells = <1>;
			#size-cells = <0>;
			depends-on-supply = <&spmi0_bus>;

			spmi@0 {
				reg = <0>;
				#address-cells = <2>;
				#size-cells = <0>;

				pmw6100_glink_debug: pmw6100-debug@0 {
					compatible = "qcom,spmi-pmic";
					reg = <0 SPMI_USID>;
					qcom,can-sleep;
				};
			};
		};

		pmic_glink_adc: qcom,glink-adc {
			compatible = "qcom,glink-adc";
			#address-cells = <1>;
			#size-cells = <0>;
			#io-channel-cells = <1>;
			status = "disabled";
		};
	};

	ddr_freq_table: ddr-freq-table {
		qcom,freq-tbl =
			<  200000 >,
			<  451200 >,
			<  547200 >,
			< 1353600 >,
			< 1555200 >,
			< 1708800 >,
			< 2092800 >,
			< 2736000 >,
			< 3187200 >,
			< 3686400 >,
			< 4224000 >;
	};

	ddrqos_freq_table: ddrqos-freq-table {
		qcom,freq-tbl =
			< 0 >,
			< 1 >;
	};

	qcom_dcvs: qcom,dcvs {
		compatible = "qcom,dcvs";
		#address-cells = <1>;
		#size-cells = <1>;
		ranges;

		qcom_l3_dcvs_hw: l3 {
			compatible = "qcom,dcvs-hw";
			qcom,dcvs-hw-type = <2>;
			qcom,bus-width = <32>;
			reg = <0x17d90000 0x4000>, <0x17d90100 0xa0>;
			reg-names = "l3-base", "l3tbl-base";

			l3_dcvs_sp: sp {
				compatible = "qcom,dcvs-path";
				qcom,dcvs-path-type = <0>;
				qcom,shared-offset = <0x0090>;
			};
		};

		qcom_ddr_dcvs_hw: ddr {
			compatible = "qcom,dcvs-hw";
			qcom,dcvs-hw-type = <0>;
			qcom,bus-width = <4>;
			qcom,freq-tbl = <&ddr_freq_table>;

			ddr_dcvs_sp: sp {
				compatible = "qcom,dcvs-path";
				qcom,dcvs-path-type = <0>;
				interconnects = <&gem_noc MASTER_APPSS_PROC
						&mc_virt SLAVE_EBI1>;
			};
		};

		qcom_ddrqos_dcvs_hw: ddrqos {
			compatible = "qcom,dcvs-hw";
			qcom,dcvs-hw-type = <3>;
			qcom,bus-width = <1>;
			qcom,freq-tbl = <&ddrqos_freq_table>;

			ddrqos_dcvs_sp: sp {
				compatible = "qcom,dcvs-path";
				qcom,dcvs-path-type = <0>;
				interconnects = <&gem_noc MASTER_APPSS_PROC
						&mc_virt SLAVE_EBI1>;
			};
		};
	};

	qcom_memlat: qcom,memlat {
		compatible = "qcom,memlat";
		ddr {
			compatible = "qcom,memlat-grp";
			qcom,target-dev = <&qcom_ddr_dcvs_hw>;
			qcom,sampling-path = <&ddr_dcvs_sp>;
			qcom,miss-ev = <0x1000>;

			silver {
				compatible = "qcom,memlat-mon";
				qcom,cpulist = <&CPU0 &CPU1 &CPU2 &CPU3>;
				qcom,sampling-enabled;
				qcom,cpufreq-memfreq-tbl =
					<  249600  200000 >,
					<  460800  451200 >,
					<  595200  547200 >,
					< 1363200  681000 >,
					< 1478400  768000 >,
					< 1747200 1353600 >,
					< 1958400 1555200 >;
			};

			gold {
				compatible = "qcom,memlat-mon";
				qcom,cpulist = <&CPU4>;
				qcom,sampling-enabled;
				qcom,cpufreq-memfreq-tbl =
					<  268800  451200 >,
					<  508800  547200 >,
					< 1190000  768000 >,
					< 1440000 1353600 >,
					< 1612000 1555200 >,
					< 1785000 1708800 >,
					< 2122000 2092800 >;
			};

			silver-compute {
				compatible = "qcom,memlat-mon";
				qcom,cpulist = <&CPU0 &CPU1 &CPU2 &CPU3>;
				qcom,sampling-enabled;
				qcom,compute-mon;
				qcom,cpufreq-memfreq-tbl =
					< 1363200 200000 >,
					< 1958400 451200 >;
			};

			gold-compute {
				compatible = "qcom,memlat-mon";
				qcom,cpulist = <&CPU4>;
				qcom,sampling-enabled;
				qcom,compute-mon;
				qcom,cpufreq-memfreq-tbl =
					< 1785000 547200 >,
					< 2122000 768000 >;
			};
		};

		l3 {
			compatible = "qcom,memlat-grp";
			qcom,target-dev = <&qcom_l3_dcvs_hw>;
			qcom,sampling-path = <&l3_dcvs_sp>;
			qcom,miss-ev = <0x17>;

			silver {
				compatible = "qcom,memlat-mon";
				qcom,cpulist = <&CPU0 &CPU1 &CPU2 &CPU3>;
				qcom,cpufreq-memfreq-tbl =
					<  249600  249600 >,
					<  460800  403200 >,
					<  595200  537600 >,
					<  902400  806400 >,
					< 1036800  902400 >,
					< 1363200 1209600 >,
					< 1478400 1305600 >,
					< 1747200 1401600 >,
					< 1958400 1612800 >;
				qcom,sampling-enabled;
			};

			gold {
				compatible = "qcom,memlat-mon";
				qcom,cpulist = <&CPU4>;
				qcom,cpufreq-memfreq-tbl =
					<  268800  249600 >,
					<  508800  403200 >,
					<  614400  537600 >,
					<  960000  806400 >,
					< 1190400  902400 >,
					< 1440000 1209600 >,
					< 1612800 1305600 >,
					< 1785600 1401600 >,
					< 2112000 1612800 >;
				qcom,sampling-enabled;
			};

			silver-compute {
				compatible = "qcom,memlat-mon";
				qcom,cpulist = <&CPU0 &CPU1 &CPU2 &CPU3>;
				qcom,cpufreq-memfreq-tbl =
					<  249600 249600 >,
					< 1958000 403200 >;
				qcom,sampling-enabled;
				qcom,compute-mon;
			};

			gold-compute {
				compatible = "qcom,memlat-mon";
				qcom,cpulist = <&CPU4>;
				qcom,cpufreq-memfreq-tbl =
					<  268800 249600 >,
					< 2112000 403200 >;
				qcom,sampling-enabled;
				qcom,compute-mon;
			};

		};

		ddrqos {
			compatible = "qcom,memlat-grp";
			qcom,target-dev = <&qcom_ddrqos_dcvs_hw>;
			qcom,sampling-path = <&ddrqos_dcvs_sp>;
			qcom,miss-ev = <0x1000>;

			ddrqos_gold_lat: gold {
				compatible = "qcom,memlat-mon";
				qcom,cpulist = <&CPU4>;
				qcom,cpufreq-memfreq-tbl =
					< 1190400 0 >,
					< 2112000 1 >;
				qcom,sampling-enabled;
			};

			ddrqos_gold_latfloor: prime-latfloor {
				compatible = "qcom,memlat-mon";
				qcom,cpulist = <&CPU4>;
				qcom,cpufreq-memfreq-tbl =
					< 1612800 0 >,
					< 2112000 1 >;
				qcom,sampling-enabled;
			};
		};
	};

	bwmon_ddr: qcom,bwmon-ddr@24091000 {
		compatible = "qcom,bwmon5";
		reg = <0x24091000 0x1000>;
		reg-names = "base";
		interrupts = <GIC_SPI 81 IRQ_TYPE_LEVEL_HIGH>;
		qcom,hw-timer-hz = <19200000>;
		qcom,count-unit = <0x10000>;
		qcom,target-dev = <&qcom_ddr_dcvs_hw>;
	};

	mmio_sram: mmio-sram@17D09100 {
		#address-cells = <2>;
		#size-cells = <2>;
		compatible = "mmio-sram";
		reg = <0x0 0x17D09100 0x0 0x200>;
		ranges = <0x0 0x0 0x0 0x17D09100 0x0 0x200>;

		cpu_scp_lpri: scmi-shmem@0 {
			compatible = "arm,scmi-shmem";
			reg = <0x0 0x17D09100 0x0 0x200>;
		};
	};

	scmi: qcom,scmi {
		#address-cells = <1>;
		#size-cells = <0>;
		compatible = "arm,scmi";
		mboxes = <&cpucp 0>;
		mbox-names = "tx";
		shmem = <&cpu_scp_lpri>;

		scmi_qcom: protocol@80 {
			reg = <0x80>;
			#clock-cells = <1>;
		};
	};

	cpucp_log: qcom,cpucp_log@D8040000 {
		compatible = "qcom,cpucp-log";
		reg = <0xD8040000 0x10000>, <0xD8050000 0x10000>;
		mboxes = <&cpucp 1>;
		qcom,log-type = <0>;
	};

	cnss_audio_iommu_group0: cnss_audio_iommu_group0 {
		qcom,iommu-msi-size = <0x1000>;
		qcom,iommu-geometry = <0x24000000 0x98010000>;
		qcom,iommu-dma = "fastmap";
		qcom,iommu-pagetable = "coherent";
		qcom,iommu-faults = "stall-disable", "HUPCF", "non-fatal";
	};

};

#include "vienna-dma-heaps.dtsi"
#include "vienna-coresight.dtsi"
#include "vienna-debug.dtsi"
#include "vienna-pinctrl.dtsi"
#include "vienna-pmic-overlay.dtsi"
#include "vienna-reserved-memory.dtsi"
#include "vienna-regulators.dtsi"
#include "msm-arm-smmu-vienna.dtsi"
#include "vienna-qupv3.dtsi"
#include "vienna-usb.dtsi"

&reserved_memory {
	#address-cells = <2>;
	#size-cells = <2>;
	ranges;

	/* global autoconfigured region for contiguous allocations */
	system_cma: linux,cma {
		compatible = "shared-dma-pool";
		alloc-ranges = <0x0 0x00000000 0x0 0xffffffff>;
		reusable;
		alignment = <0x0 0x400000>;
		size = <0x0 0x1000000>;
		linux,cma-default;
	};

	adsp_mem_heap: adsp_heap_region {
		compatible = "shared-dma-pool";
		alloc-ranges = <0x0 0x00000000 0x0 0xffffffff>;
		reusable;
		alignment = <0x0 0x400000>;
		size = <0x0 0x800000>;
	};

	qseecom_mem: qseecom_region {
		compatible = "shared-dma-pool";
		alloc-ranges = <0x0 0x00000000 0x0 0xffffffff>;
		reusable;
		alignment = <0x0 0x400000>;
		size = <0x0 0x1400000>;
	};

	qseecom_ta_mem: qseecom_ta_region {
		compatible = "shared-dma-pool";
		alloc-ranges = <0x0 0x00000000 0x0 0xffffffff>;
		reusable;
		alignment = <0x0 0x400000>;
		size = <0x0 0x1000000>;
	};
};

&uart4 {
	status = "ok";
};

&uart6 {
	qcom,auto-suspend-disable;
	status = "ok";
};

&pmic_glink_debug {
	spmi@0 {
		reg = <0>;
		#address-cells = <2>;
		#size-cells = <0>;
		qcom,pmw6100-debug@0 {
			compatible = "qcom,spmi-pmic";
			reg = <0 SPMI_USID>;
			qcom,can-sleep;
		};
	};
};

&usb0 {
	usb-role-switch;
	port {
		usb_port0: endpoint {
			remote-endpoint = <&usb_port0_connector>;
		};
	};
};

&ucsi {
	connector {
		port {
			usb_port0_connector: endpoint {
				remote-endpoint = <&usb_port0>;
			};
		};
	};
};

&i2c9 {
	status = "ok";

	raydium_ts@39 {
		compatible = "raydium,raydium-ts";
		reg = <0x39>;
		status = "ok";
		interrupt-parent = <&tlmm>;
		interrupts = <113 0x2008>;
		vcc_i2c-supply = <&L15A>;
		pinctrl-names = "pmx_ts_active","pmx_ts_suspend","pmx_ts_release";
		pinctrl-0 = <&ts_int_active &ts_reset_active>;
		pinctrl-1 = <&ts_int_suspend &ts_reset_suspend>;
		pinctrl-2 = <&ts_release>;
		raydium,reset-gpio = <&tlmm 114 0x00>;
		raydium,irq-gpio = <&tlmm 113 0x00>;
		raydium,num-max-touches = <2>;
		raydium,soft-reset-delay-ms = <50>;
		raydium,hard-reset-delay-ms = <100>;
		raydium,x_max = <454>;
		raydium,y_max = <454>;
		raydium,display-coords= <0 0 454 454>;
	};
};

#include "ipcc-test-vienna.dtsi"
#include "vienna-walt.dtsi"
#include "msm-rdbg.dtsi"
/delete-node/ &ipcc_self_ping_adsp;
/delete-node/ &ipcc_self_ping_cdsp;
/delete-node/ &ipcc_self_ping_slpi;

#include "vienna-thermal.dtsi"
#include "vienna-thermal-overlay.dtsi"
